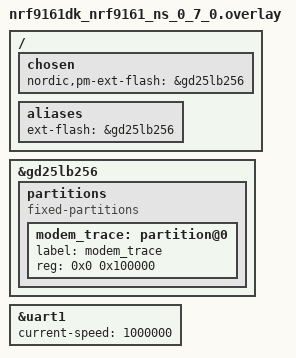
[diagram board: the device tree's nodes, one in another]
/*
 * Copyright (c) 2022 Nordic Semiconductor ASA
 *
 * SPDX-License-Identifier: LicenseRef-Nordic-5-Clause
 */

/delete-node/ &gd25wb256;

/ {
	chosen {
		nordic,pm-ext-flash = &gd25lb256;
	};

	aliases {
		ext-flash = &gd25lb256;
	};
};

&gd25lb256 {
	status = "okay";

	partitions {
		compatible = "fixed-partitions";
		#address-cells = <1>;
		#size-cells = <1>;

		modem_trace: partition@0 {
			label = "modem_trace";
			reg = <0x0 0x100000>; /* 1 MB */
		};
	};
};

/* Enable UART1 at 1 megabaud for printing modem traces  */
&uart1 {
	status = "okay";
	current-speed = <1000000>;
};
